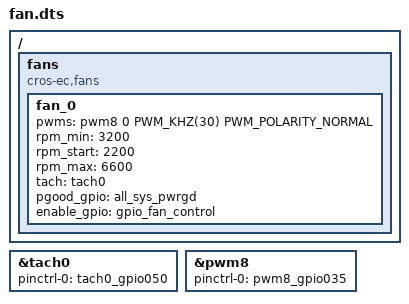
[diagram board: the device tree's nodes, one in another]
/* Copyright 2022 The Chromium OS Authors. All rights reserved.
 * Use of this source code is governed by a BSD-style license that can be
 * found in the LICENSE file.
 */

/ {
	fans {
		compatible = "cros-ec,fans";

		fan_0 {
			pwms = <&pwm8 0 PWM_KHZ(30) PWM_POLARITY_NORMAL>;
			rpm_min = <3200>;
			rpm_start = <2200>;
			rpm_max = <6600>;
			tach = <&tach0>;
			pgood_gpio = <&all_sys_pwrgd>;
			enable_gpio = <&gpio_fan_control>;
		};
	};
};

/* Tachemeter for fan speed measurement */
&tach0 {
	status = "okay";
	pinctrl-0 = <&tach0_gpio050>; /* TACH0 input on GPI050 */
	pinctrl-names = "default";
	/* port = <NPCX_TACH_PORT_A>; port-A is selected */
	/* sample-clk = <NPCX_TACH_FREQ_LFCLK>; Use LFCLK as sampling clock */
	/* pulses-per-round = <2>; number of pulses per round of encoder */
};

&pwm8 {
	status = "okay";
	pinctrl-0 = <&pwm8_gpio035>;
	pinctrl-names = "default";
};
